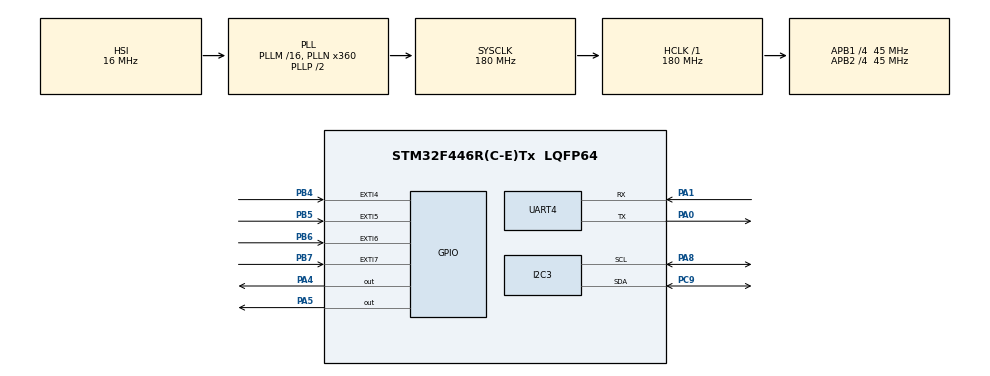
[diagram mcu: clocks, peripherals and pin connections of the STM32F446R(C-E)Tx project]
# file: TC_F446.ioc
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Mcu.Family=STM32F4
Mcu.Name=STM32F446R(C-E)Tx
Mcu.Package=LQFP64
NVIC.EXTI4_IRQn=true\:0\:0\:false\:false\:true\:true\:true
NVIC.EXTI9_5_IRQn=true\:0\:0\:false\:false\:true\:true\:true
NVIC.PriorityGroup=NVIC_PRIORITYGROUP_4
NVIC.TIM7_IRQn=true\:1\:0\:true\:false\:true\:true\:true
PA0-WKUP.Mode=Asynchronous
PA0-WKUP.Signal=UART4_TX
PA1.Mode=Asynchronous
PA1.Signal=UART4_RX
PA4.GPIO_PuPd=GPIO_PULLDOWN
PA4.Signal=GPIO_Output
PA5.GPIO_PuPd=GPIO_PULLDOWN
PA5.Signal=GPIO_Output
PA8.Mode=I2C
PA8.Signal=I2C3_SCL
PB4.GPIO_PuPd=GPIO_PULLUP
PB4.Signal=GPXTI4
PB5.GPIO_PuPd=GPIO_PULLUP
PB5.Signal=GPXTI5
PB6.GPIO_PuPd=GPIO_PULLUP
PB6.Signal=GPXTI6
PB7.GPIO_PuPd=GPIO_PULLUP
PB7.Signal=GPXTI7
PC9.Mode=I2C
PC9.Signal=I2C3_SDA
ProjectManager.HeapSize=0x200
ProjectManager.StackSize=0x400
ProjectManager.TargetToolchain=Makefile
RCC.AHBFreq_Value=180000000
RCC.APB1CLKDivider=RCC_HCLK_DIV4
RCC.APB1Freq_Value=45000000
RCC.APB1TimFreq_Value=90000000
RCC.APB2CLKDivider=RCC_HCLK_DIV4
RCC.APB2Freq_Value=45000000
RCC.APB2TimFreq_Value=90000000
RCC.CortexFreq_Value=180000000
RCC.HCLKFreq_Value=180000000
RCC.PLLN=360
RCC.SYSCLKFreq_VALUE=180000000
RCC.SYSCLKSource=RCC_SYSCLKSOURCE_PLLCLK
RCC.USBFreq_Value=180000000
RCC.VCOOutputFreq_Value=360000000
TIM2.Period=3600000000
TIM2.Prescaler=9999
TIM3.Period=54000
TIM3.Prescaler=9999
TIM4.Period=54000
TIM4.Prescaler=9999
TIM5.Period=3600000000
TIM5.Prescaler=9999
TIM7.Period=15
TIM7.Prescaler=59999
UART4.VirtualMode=Asynchronous
VP_TIM2_VS_ClockSourceINT.Mode=Internal
VP_TIM3_VS_ClockSourceINT.Mode=Internal
VP_TIM4_VS_ClockSourceINT.Mode=Internal
VP_TIM5_VS_ClockSourceINT.Mode=Internal
VP_TIM7_VS_ClockSourceINT.Mode=Enable_Timer
board=custom

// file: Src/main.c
/* USER CODE BEGIN Header */
/**
  ******************************************************************************
  * @file           : main.c
  * @brief          : Main program body
  ******************************************************************************
  * @attention
  *
  * <h2><center>&copy; Copyright (c) 2019 STMicroelectronics.
  * All rights reserved.</center></h2>
  *
  * This software component is licensed by ST under BSD 3-Clause license,
  * the "License"; You may not use this file except in compliance with the
  * License. You may obtain a copy of the License at:
  *                        opensource.org/licenses/BSD-3-Clause
  *
  ******************************************************************************
  */
/* USER CODE END Header */

#include "main.h"

/* USER CODE BEGIN Includes */
#include <stdlib.h>
/* USER CODE END Includes */

I2C_HandleTypeDef hi2c3;

TIM_HandleTypeDef htim2;
TIM_HandleTypeDef htim3;
TIM_HandleTypeDef htim4;
TIM_HandleTypeDef htim5;
TIM_HandleTypeDef htim7;

UART_HandleTypeDef huart4;

/* USER CODE BEGIN PV */
volatile uint32_t pulses[4];

float setpoint = 0.1;
int bias = 0;

float kp = 3;
float ki = 90;
float kd = 0.02;
float dt = 0.005;
uint32_t cornering_threshold = 2000;

volatile float integral = 0;
volatile float derivative = 0;
volatile float slip_ratio = 0;

volatile uint32_t control = 0;
volatile uint32_t slip = 0;
volatile float error = 0;
volatile uint32_t prev_error = 0;
volatile uint32_t front_sum = 0;
volatile uint32_t back_sum = 0;

int tc_on = 1;

/* USER CODE END PV */

void SystemClock_Config(void);
static void MX_GPIO_Init(void);
static void MX_TIM2_Init(void);
static void MX_TIM3_Init(void);
static void MX_TIM4_Init(void);
static void MX_TIM5_Init(void);
static void MX_I2C3_Init(void);
static void MX_TIM7_Init(void);
static void MX_UART4_Init(void);

int main(void)
{

  /* MCU Configuration--------------------------------------------------------*/

  /* Reset of all peripherals, Initializes the Flash interface and the Systick. */
  HAL_Init();

  /* Configure the system clock */
  SystemClock_Config();

  /* Initialize all configured peripherals */
  MX_GPIO_Init();
  MX_TIM2_Init();
  MX_TIM3_Init();
  MX_TIM4_Init();
  MX_TIM5_Init();
  MX_I2C3_Init();
  MX_TIM7_Init();
  MX_UART4_Init();

  /* Infinite loop */
  while (1)
  {
    HAL_GPIO_TogglePin(GPIOB,GPIO_PIN_13);
    HAL_Delay(500);
  }
}

void SystemClock_Config(void)
{
  RCC_OscInitTypeDef RCC_OscInitStruct = {0};
  RCC_ClkInitTypeDef RCC_ClkInitStruct = {0};

  /** Configure the main internal regulator output voltage
  */
  __HAL_RCC_PWR_CLK_ENABLE();
  __HAL_PWR_VOLTAGESCALING_CONFIG(PWR_REGULATOR_VOLTAGE_SCALE1);
  /** Initializes the CPU, AHB and APB busses clocks
  */
  RCC_OscInitStruct.OscillatorType = RCC_OSCILLATORTYPE_HSI;
  RCC_OscInitStruct.HSIState = RCC_HSI_ON;
  RCC_OscInitStruct.HSICalibrationValue = RCC_HSICALIBRATION_DEFAULT;
  RCC_OscInitStruct.PLL.PLLState = RCC_PLL_ON;
  RCC_OscInitStruct.PLL.PLLSource = RCC_PLLSOURCE_HSI;
  RCC_OscInitStruct.PLL.PLLM = 16;
  RCC_OscInitStruct.PLL.PLLN = 360;
  RCC_OscInitStruct.PLL.PLLP = RCC_PLLP_DIV2;
  RCC_OscInitStruct.PLL.PLLQ = 2;
  RCC_OscInitStruct.PLL.PLLR = 2;
  if (HAL_RCC_OscConfig(&RCC_OscInitStruct) != HAL_OK)
  {
    Error_Handler();
  }
  /** Activate the Over-Drive mode
  */
  if (HAL_PWREx_EnableOverDrive() != HAL_OK)
  {
    Error_Handler();
  }
  /** Initializes the CPU, AHB and APB busses clocks
  */
  RCC_ClkInitStruct.ClockType = RCC_CLOCKTYPE_HCLK|RCC_CLOCKTYPE_SYSCLK
                              |RCC_CLOCKTYPE_PCLK1|RCC_CLOCKTYPE_PCLK2;
  RCC_ClkInitStruct.SYSCLKSource = RCC_SYSCLKSOURCE_PLLCLK;
  RCC_ClkInitStruct.AHBCLKDivider = RCC_SYSCLK_DIV1;
  RCC_ClkInitStruct.APB1CLKDivider = RCC_HCLK_DIV4;
  RCC_ClkInitStruct.APB2CLKDivider = RCC_HCLK_DIV4;

  if (HAL_RCC_ClockConfig(&RCC_ClkInitStruct, FLASH_LATENCY_5) != HAL_OK)
  {
    Error_Handler();
  }
}

static void MX_I2C3_Init(void)
{

  hi2c3.Instance = I2C3;
  hi2c3.Init.ClockSpeed = 100000;
  hi2c3.Init.DutyCycle = I2C_DUTYCYCLE_2;
  hi2c3.Init.OwnAddress1 = 0;
  hi2c3.Init.AddressingMode = I2C_ADDRESSINGMODE_7BIT;
  hi2c3.Init.DualAddressMode = I2C_DUALADDRESS_DISABLE;
  hi2c3.Init.OwnAddress2 = 0;
  hi2c3.Init.GeneralCallMode = I2C_GENERALCALL_DISABLE;
  hi2c3.Init.NoStretchMode = I2C_NOSTRETCH_DISABLE;
  if (HAL_I2C_Init(&hi2c3) != HAL_OK)
  {
    Error_Handler();
  }

}

static void MX_TIM2_Init(void)
{

  TIM_ClockConfigTypeDef sClockSourceConfig = {0};
  TIM_MasterConfigTypeDef sMasterConfig = {0};

  htim2.Instance = TIM2;
  htim2.Init.Prescaler = 9999;
  htim2.Init.CounterMode = TIM_COUNTERMODE_UP;
  htim2.Init.Period = 3600000000;
  htim2.Init.ClockDivision = TIM_CLOCKDIVISION_DIV1;
  htim2.Init.AutoReloadPreload = TIM_AUTORELOAD_PRELOAD_DISABLE;
  if (HAL_TIM_Base_Init(&htim2) != HAL_OK)
  {
    Error_Handler();
  }
  sClockSourceConfig.ClockSource = TIM_CLOCKSOURCE_INTERNAL;
  if (HAL_TIM_ConfigClockSource(&htim2, &sClockSourceConfig) != HAL_OK)
  {
    Error_Handler();
  }
  sMasterConfig.MasterOutputTrigger = TIM_TRGO_RESET;
  sMasterConfig.MasterSlaveMode = TIM_MASTERSLAVEMODE_DISABLE;
  if (HAL_TIMEx_MasterConfigSynchronization(&htim2, &sMasterConfig) != HAL_OK)
  {
    Error_Handler();
  }
  /* USER CODE BEGIN TIM2_Init 2 */
  HAL_TIM_Base_Start_IT(&htim2);
  /* USER CODE END TIM2_Init 2 */

}

static void MX_TIM3_Init(void)
{

  TIM_ClockConfigTypeDef sClockSourceConfig = {0};
  TIM_MasterConfigTypeDef sMasterConfig = {0};

  htim3.Instance = TIM3;
  htim3.Init.Prescaler = 9999;
  htim3.Init.CounterMode = TIM_COUNTERMODE_UP;
  htim3.Init.Period = 54000;
  htim3.Init.ClockDivision = TIM_CLOCKDIVISION_DIV1;
  htim3.Init.AutoReloadPreload = TIM_AUTORELOAD_PRELOAD_DISABLE;
  if (HAL_TIM_Base_Init(&htim3) != HAL_OK)
  {
    Error_Handler();
  }
  sClockSourceConfig.ClockSource = TIM_CLOCKSOURCE_INTERNAL;
  if (HAL_TIM_ConfigClockSource(&htim3, &sClockSourceConfig) != HAL_OK)
  {
    Error_Handler();
  }
  sMasterConfig.MasterOutputTrigger = TIM_TRGO_RESET;
  sMasterConfig.MasterSlaveMode = TIM_MASTERSLAVEMODE_DISABLE;
  if (HAL_TIMEx_MasterConfigSynchronization(&htim3, &sMasterConfig) != HAL_OK)
  {
    Error_Handler();
  }
  /* USER CODE BEGIN TIM3_Init 2 */
  HAL_TIM_Base_Start_IT(&htim3);
  /* USER CODE END TIM3_Init 2 */

}

static void MX_TIM4_Init(void)
{

  TIM_ClockConfigTypeDef sClockSourceConfig = {0};
  TIM_MasterConfigTypeDef sMasterConfig = {0};

  htim4.Instance = TIM4;
  htim4.Init.Prescaler = 9999;
  htim4.Init.CounterMode = TIM_COUNTERMODE_UP;
  htim4.Init.Period = 54000;
  htim4.Init.ClockDivision = TIM_CLOCKDIVISION_DIV1;
  htim4.Init.AutoReloadPreload = TIM_AUTORELOAD_PRELOAD_DISABLE;
  if (HAL_TIM_Base_Init(&htim4) != HAL_OK)
  {
    Error_Handler();
  }
  sClockSourceConfig.ClockSource = TIM_CLOCKSOURCE_INTERNAL;
  if (HAL_TIM_ConfigClockSource(&htim4, &sClockSourceConfig) != HAL_OK)
  {
    Error_Handler();
  }
  sMasterConfig.MasterOutputTrigger = TIM_TRGO_RESET;
  sMasterConfig.MasterSlaveMode = TIM_MASTERSLAVEMODE_DISABLE;
  if (HAL_TIMEx_MasterConfigSynchronization(&htim4, &sMasterConfig) != HAL_OK)
  {
    Error_Handler();
  }
  /* USER CODE BEGIN TIM4_Init 2 */
  HAL_TIM_Base_Start_IT(&htim4);
  /* USER CODE END TIM4_Init 2 */

}

static void MX_TIM5_Init(void)
{

  TIM_ClockConfigTypeDef sClockSourceConfig = {0};
  TIM_MasterConfigTypeDef sMasterConfig = {0};

  htim5.Instance = TIM5;
  htim5.Init.Prescaler = 9999;
  htim5.Init.CounterMode = TIM_COUNTERMODE_UP;
  htim5.Init.Period = 3600000000;
  htim5.Init.ClockDivision = TIM_CLOCKDIVISION_DIV1;
  htim5.Init.AutoReloadPreload = TIM_AUTORELOAD_PRELOAD_DISABLE;
  if (HAL_TIM_Base_Init(&htim5) != HAL_OK)
  {
    Error_Handler();
  }
  sClockSourceConfig.ClockSource = TIM_CLOCKSOURCE_INTERNAL;
  if (HAL_TIM_ConfigClockSource(&htim5, &sClockSourceConfig) != HAL_OK)
  {
    Error_Handler();
  }
  sMasterConfig.MasterOutputTrigger = TIM_TRGO_RESET;
  sMasterConfig.MasterSlaveMode = TIM_MASTERSLAVEMODE_DISABLE;
  if (HAL_TIMEx_MasterConfigSynchronization(&htim5, &sMasterConfig) != HAL_OK)
  {
    Error_Handler();
  }
  /* USER CODE BEGIN TIM5_Init 2 */
  HAL_TIM_Base_Start_IT(&htim5);
  /* USER CODE END TIM5_Init 2 */

}

static void MX_TIM7_Init(void)
{

  TIM_MasterConfigTypeDef sMasterConfig = {0};

  htim7.Instance = TIM7;
  htim7.Init.Prescaler = 59999;
  htim7.Init.CounterMode = TIM_COUNTERMODE_UP;
  htim7.Init.Period = 15;
  htim7.Init.AutoReloadPreload = TIM_AUTORELOAD_PRELOAD_DISABLE;
  if (HAL_TIM_Base_Init(&htim7) != HAL_OK)
  {
    Error_Handler();
  }
  sMasterConfig.MasterOutputTrigger = TIM_TRGO_RESET;
  sMasterConfig.MasterSlaveMode = TIM_MASTERSLAVEMODE_DISABLE;
  if (HAL_TIMEx_MasterConfigSynchronization(&htim7, &sMasterConfig) != HAL_OK)
  {
    Error_Handler();
  }
  /* USER CODE BEGIN TIM7_Init 2 */
  HAL_TIM_Base_Start_IT(&htim7);
  /* USER CODE END TIM7_Init 2 */

}

static void MX_UART4_Init(void)
{

  huart4.Instance = UART4;
  huart4.Init.BaudRate = 115200;
  huart4.Init.WordLength = UART_WORDLENGTH_8B;
  huart4.Init.StopBits = UART_STOPBITS_1;
  huart4.Init.Parity = UART_PARITY_NONE;
  huart4.Init.Mode = UART_MODE_TX_RX;
  huart4.Init.HwFlowCtl = UART_HWCONTROL_NONE;
  huart4.Init.OverSampling = UART_OVERSAMPLING_16;
  if (HAL_UART_Init(&huart4) != HAL_OK)
  {
    Error_Handler();
  }

}

static void MX_GPIO_Init(void)
{
  GPIO_InitTypeDef GPIO_InitStruct = {0};

  /* GPIO Ports Clock Enable */
  __HAL_RCC_GPIOA_CLK_ENABLE();
  __HAL_RCC_GPIOC_CLK_ENABLE();
  __HAL_RCC_GPIOB_CLK_ENABLE();

  /*Configure GPIO pin Output Level */
  HAL_GPIO_WritePin(GPIOA, GPIO_PIN_4|GPIO_PIN_5, GPIO_PIN_RESET);

  /*Configure GPIO pins : PA4 PA5 */
  GPIO_InitStruct.Pin = GPIO_PIN_4|GPIO_PIN_5;
  GPIO_InitStruct.Mode = GPIO_MODE_OUTPUT_PP;
  GPIO_InitStruct.Pull = GPIO_PULLDOWN;
  GPIO_InitStruct.Speed = GPIO_SPEED_FREQ_LOW;
  HAL_GPIO_Init(GPIOA, &GPIO_InitStruct);

  GPIO_InitStruct.Pin = GPIO_PIN_13;
  GPIO_InitStruct.Mode = GPIO_MODE_OUTPUT_PP;
  GPIO_InitStruct.Pull = GPIO_NOPULL;
  GPIO_InitStruct.Speed = GPIO_SPEED_FREQ_LOW;
  HAL_GPIO_Init(GPIOB, &GPIO_InitStruct);

  /*Configure GPIO pins : PB4 PB5 PB6 PB7 */
  GPIO_InitStruct.Pin = GPIO_PIN_4|GPIO_PIN_5|GPIO_PIN_6|GPIO_PIN_7;
  GPIO_InitStruct.Mode = GPIO_MODE_IT_RISING;
  GPIO_InitStruct.Pull = GPIO_PULLUP;
  HAL_GPIO_Init(GPIOB, &GPIO_InitStruct);

  /* EXTI interrupt init*/
  HAL_NVIC_SetPriority(EXTI4_IRQn, 0, 0);
  HAL_NVIC_EnableIRQ(EXTI4_IRQn);

  HAL_NVIC_SetPriority(EXTI9_5_IRQn, 0, 0);
  HAL_NVIC_EnableIRQ(EXTI9_5_IRQn);

}

/* USER CODE BEGIN 4 */
/**
  * @brief This function handles EXTI line 4 interrupt.
  */
void EXTI4_IRQHandler(void)
{
  /* USER CODE BEGIN EXTI4_IRQn 0 */
  if(__HAL_GPIO_EXTI_GET_IT(GPIO_PIN_4) != RESET){
    pulses[0] = __HAL_TIM_GET_COUNTER(&htim2);
    __HAL_TIM_SET_COUNTER(&htim2, 0);
  }
  /* USER CODE END EXTI4_IRQn 0 */
  HAL_GPIO_EXTI_IRQHandler(GPIO_PIN_4);
  /* USER CODE BEGIN EXTI4_IRQn 1 */

  /* USER CODE END EXTI4_IRQn 1 */
}

/**
  * @brief This function handles EXTI line[9:5] interrupts.
  */
void EXTI9_5_IRQHandler(void)
{
  /* USER CODE BEGIN EXTI9_5_IRQn 0 */
  if(__HAL_GPIO_EXTI_GET_IT(GPIO_PIN_5) != RESET){
    pulses[1] = __HAL_TIM_GET_COUNTER(&htim3);
    __HAL_TIM_SET_COUNTER(&htim3, 0);
  } else if(__HAL_GPIO_EXTI_GET_IT(GPIO_PIN_6) != RESET){
    pulses[2] = __HAL_TIM_GET_COUNTER(&htim4);
    __HAL_TIM_SET_COUNTER(&htim4, 0);
  } else if(__HAL_GPIO_EXTI_GET_IT(GPIO_PIN_7) != RESET){
    pulses[3] = __HAL_TIM_GET_COUNTER(&htim5);
    __HAL_TIM_SET_COUNTER(&htim5, 0);
  }
  /* USER CODE END EXTI9_5_IRQn 0 */
  HAL_GPIO_EXTI_IRQHandler(GPIO_PIN_5);
  HAL_GPIO_EXTI_IRQHandler(GPIO_PIN_6);
  HAL_GPIO_EXTI_IRQHandler(GPIO_PIN_7);
  /* USER CODE BEGIN EXTI9_5_IRQn 1 */

  /* USER CODE END EXTI9_5_IRQn 1 */
}

/**
  * @brief This function handles TIM7 global interrupt.
  * Fires every 5ms and triggers the PID algorithm to execute
  */
void TIM7_IRQHandler(void)
{
  /* USER CODE BEGIN TIM7_IRQn 0 */

  /* USER CODE END TIM7_IRQn 0 */
  HAL_TIM_IRQHandler(&htim7);
  /* USER CODE BEGIN TIM7_IRQn 1 */
  /* Transmit a UART message with the pulses[3] value along with a test message to verify UART is working */
  // uint32_t value = pulses[3];
  // unsigned char test[] = {"Test\n"};
  // unsigned char transform[20];
  // sprintf(transform, "%ld\n", value);
  // HAL_UART_Transmit(&huart4, test, sizeof(test), 1000);
  // HAL_UART_Transmit(&huart4, transform, sizeof(transform), 1000);

  if(pulses[3] >450){  // 18000/0.849*24
      HAL_GPIO_WritePin(GPIOA, GPIO_PIN_4, GPIO_PIN_SET);
      // HAL_GPIO_WritePin(GPIOA, GPIO_PIN_5, GPIO_PIN_SET); // Onboard LED
  } else {
      HAL_GPIO_WritePin(GPIOA, GPIO_PIN_4, GPIO_PIN_RESET);
      // HAL_GPIO_WritePin(GPIOA, GPIO_PIN_5, GPIO_PIN_RESET); // Onboard LED
  }

  if(pulses[0] > 54000 || pulses[3] > 54000){ // pulse length of pulses[1,2] is invalid
    control = 255;
  } else if(/*abs(pulses[0] - pulses[2]) > cornering_threshold || */abs(pulses[2] - pulses[3]) > cornering_threshold){ // cornering
    control = 255;
  } else {
    front_sum = pulses[0]+pulses[1];
    back_sum = pulses[2]+pulses[3];
    slip = back_sum - front_sum;
    slip_ratio = slip/front_sum;
    prev_error = error;
    error = slip_ratio - setpoint;

    integral += dt * error;
    derivative = (error-prev_error) / dt;

    control = bias + kp * error + ki * integral + kd * derivative;
  }

  unsigned char data[2];
  data[0] = 0x00;
  data[1] = control;
  if (HAL_I2C_Master_Transmit(&hi2c3, (0b0101111)<<1, data, sizeof(data), 1000) == HAL_OK)
  {
    //HAL_GPIO_TogglePin(GPIOC, GPIO_PIN_13);
  }

  /* USER CODE END TIM7_IRQn 1 */
}
/* USER CODE END 4 */

void Error_Handler(void)
{
}

/************************ (C) COPYRIGHT STMicroelectronics *****END OF FILE****/
